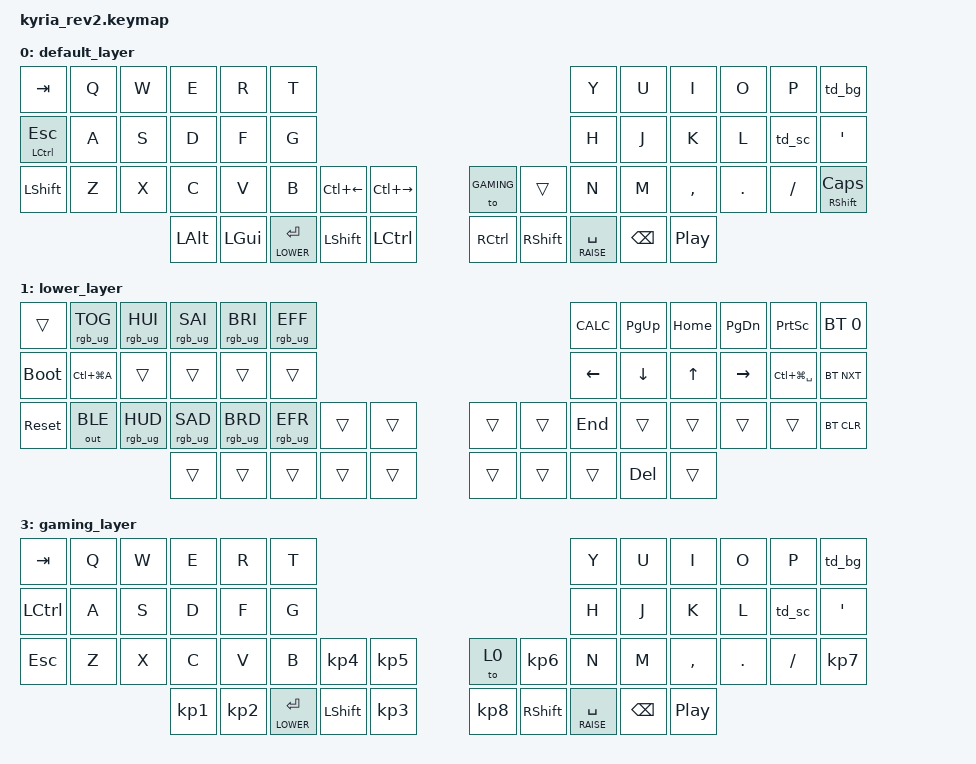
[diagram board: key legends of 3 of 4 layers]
/*
 * Copyright (c) 2020 The ZMK Contributors
 *
 * SPDX-License-Identifier: MIT
 */

#include <behaviors.dtsi>
#include <dt-bindings/zmk/bt.h>
#include <dt-bindings/zmk/keys.h>
#include <dt-bindings/zmk/outputs.h>
#include <dt-bindings/zmk/rgb.h>

/ {
  behaviors {
    td_bg: bsls_grv {
        compatible = "zmk,behavior-tap-dance";
        label = "BSLS_GRV";
        #binding-cells = <0>;
        tapping-term-ms = <200>;
        bindings = <&kp BSLH>, <&kp GRAVE>;
    };
    td_sc: semi_colon {
        compatible = "zmk,behavior-tap-dance";
        label = "SEMI_COLON";
        #binding-cells = <0>;
        tapping-term-ms = <200>;
        bindings = <&kp SEMICOLON>, <&kp COLON>;
    };
    td_hl: hash_lbrc {
        compatible = "zmk,behavior-tap-dance";
        label = "HASH_LBRC";
        #binding-cells = <0>;
        tapping-term-ms = <200>;
        bindings = <&kp HASH>, <&kp LBRC>;
    };
    td_ar: astrk_rbrc {
        compatible = "zmk,behavior-tap-dance";
        label = "ASTRK_RBRC";
        #binding-cells = <0>;
        tapping-term-ms = <200>;
        bindings = <&kp ASTRK>, <&kp RBRC>;
    };
    td_dl: dollar_lpar {
        compatible = "zmk,behavior-tap-dance";
        label = "DOLLAR_LPAR";
        #binding-cells = <0>;
        tapping-term-ms = <200>;
        bindings = <&kp DOLLAR>, <&kp LPAR>;
    };
    td_arp: ampersand_rpar {
        compatible = "zmk,behavior-tap-dance";
        label = "AMPERSAND_RPAR";
        #binding-cells = <0>;
        tapping-term-ms = <200>;
        bindings = <&kp AMPERSAND>, <&kp RPAR>;
    };
    td_pl: percent_lbkt {
        compatible = "zmk,behavior-tap-dance";
        label = "PERCENT_LBKT";
        #binding-cells = <0>;
        tapping-term-ms = <200>;
        bindings = <&kp PERCENT>, <&kp LBKT>;
    };
    td_cr: caret_rbkt {
        compatible = "zmk,behavior-tap-dance";
        label = "CARET_RBKT";
        #binding-cells = <0>;
        tapping-term-ms = <200>;
        bindings = <&kp CARET>, <&kp RBKT>;
    };
    td_um: underscore_minus {
        compatible = "zmk,behavior-tap-dance";
        label = "UNDERSCORE_MINUS";
        #binding-cells = <0>;
        tapping-term-ms = <200>;
        bindings = <&kp UNDERSCORE>, <&kp MINUS>;
    };
    td_pe: plus_equal {
        compatible = "zmk,behavior-tap-dance";
        label = "PLUS_EQUAL";
        #binding-cells = <0>;
        tapping-term-ms = <200>;
        bindings = <&kp PLUS>, <&kp EQUAL>;
    };
  };

  #define DEFAULT 0
  #define LOWER   1
  #define RAISE   2
  #define GAMING  3

	keymap {
		compatible = "zmk,keymap";

		default_layer {
			bindings = <
	&kp TAB       &kp Q &kp W &kp E &kp R &kp T                                                &kp Y &kp U  &kp I     &kp O   &kp P    &td_bg
	&mt LCTRL ESC &kp A &kp S &kp D &kp F &kp G                                                &kp H &kp J  &kp K     &kp L   &td_sc &kp SQT
	&kp LSHFT     &kp Z &kp X &kp C &kp V &kp B &kp LC(LEFT) &kp LC(RIGHT)  &to GAMING &trans     &kp N &kp M  &kp COMMA &kp DOT &kp FSLH &mt RSHFT CAPS
	       &kp LALT &kp LGUI &lt LOWER RET &kp LSHIFT &kp LCTRL           &kp RCTRL &kp RSHIFT &lt RAISE SPACE &kp BSPC &kp C_PLAY_PAUSE
			>;

			sensor-bindings = <&inc_dec_kp N0 N0 &inc_dec_kp C_PREV C_NEXT>;
		};

		lower_layer {
			bindings = <
	&trans &rgb_ug RGB_TOG &rgb_ug RGB_HUI &rgb_ug RGB_SAI &rgb_ug RGB_BRI &rgb_ug RGB_EFF                             &kp K_CALC &kp PG_UP  &kp HOME &kp PG_DN &kp PSCRN &bt BT_SEL 0
  &bootloader &kp LC(LG(A))  &trans &trans &trans &trans                                                                 &kp LEFT   &kp DOWN   &kp UP  &kp RIGHT &kp LC(LG(SPACE))    &bt BT_NXT
	&sys_reset &out OUT_BLE    &rgb_ug RGB_HUD &rgb_ug RGB_SAD &rgb_ug RGB_BRD &rgb_ug RGB_EFR &trans &trans &trans &trans &kp END &trans  &trans    &trans    &trans    &bt BT_CLR
	                                                                  &trans &trans &trans &trans &trans &trans &trans &trans  &kp DEL &trans
			>;
			sensor-bindings = <&inc_dec_kp N0 N0 &inc_dec_kp C_BRI_DN C_BRI_UP>;
		};

		raise_layer {
			bindings = <
	&trans &kp EXCL &kp AT &td_hl &td_dl &td_pl  &td_cr &td_arp &td_ar &td_um &td_pe  &kp F12
  &trans &kp N1   &kp N2 &kp N3 &kp N4 &kp N5  &kp N6 &kp N7  &kp N8 &kp N9 &kp N0  &kp F11
  &trans &kp F1   &kp F2 &kp F3 &kp F4 &kp F5  &kp F6 &kp F7  &kp F8 &kp F9 &kp F10 &trans
  &trans &trans &trans &trans &trans &trans &trans &trans &trans &trans
			>;
		};

		gaming_layer {
			bindings = <
	&kp TAB   &kp Q &kp W &kp E &kp R &kp T                                                &kp Y &kp U  &kp I     &kp O   &kp P    &td_bg
	&kp LCTRL &kp A &kp S &kp D &kp F &kp G                                                &kp H &kp J  &kp K     &kp L   &td_sc &kp SQT
	&kp ESC   &kp Z &kp X &kp C &kp V &kp B &kp KP_N4       &kp KP_N5         &to 0      &kp KP_N6     &kp N &kp M  &kp COMMA &kp DOT &kp FSLH &kp KP_N7
	       &kp KP_N1   &kp KP_N2   &lt LOWER RET &kp LSHIFT &kp KP_N3              &kp KP_N8    &kp RSHIFT &lt RAISE SPACE &kp BSPC &kp C_PLAY_PAUSE
			>;

			sensor-bindings = <&inc_dec_kp N0 N0 &inc_dec_kp C_PREV C_NEXT>;
		};
	};
};
